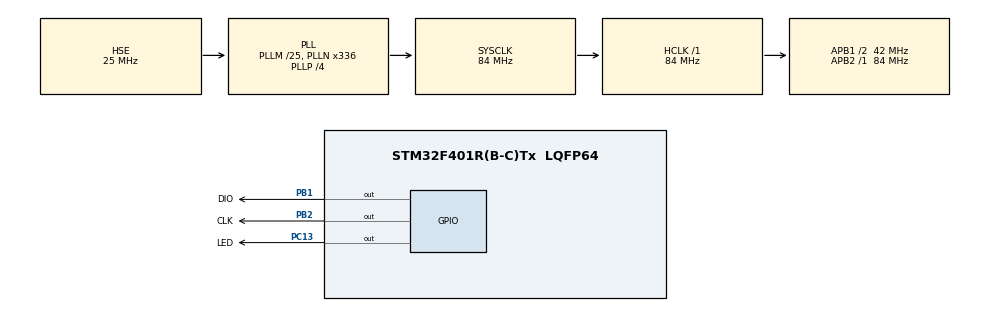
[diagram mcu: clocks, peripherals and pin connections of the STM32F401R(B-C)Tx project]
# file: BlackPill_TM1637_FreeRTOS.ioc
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FREERTOS.Tasks01=defaultTask,24,128,StartDefaultTask,Default,NULL,Dynamic,NULL,NULL
Mcu.Family=STM32F4
Mcu.Name=STM32F401R(B-C)Tx
Mcu.Package=LQFP64
NVIC.PriorityGroup=NVIC_PRIORITYGROUP_4
NVIC.TIM1_TRG_COM_TIM11_IRQn=true\:15\:0\:false\:false\:true\:false\:false\:true\:true
NVIC.TimeBase=TIM1_TRG_COM_TIM11_IRQn
NVIC.TimeBaseIP=TIM11
PB1.GPIO_Label=DIO
PB1.GPIO_ModeDefaultOutputPP=GPIO_MODE_OUTPUT_OD
PB1.GPIO_PuPd=GPIO_NOPULL
PB1.GPIO_Speed=GPIO_SPEED_FREQ_VERY_HIGH
PB1.PinState=GPIO_PIN_SET
PB1.Signal=GPIO_Output
PB2.GPIO_Label=CLK
PB2.GPIO_ModeDefaultOutputPP=GPIO_MODE_OUTPUT_OD
PB2.GPIO_PuPd=GPIO_NOPULL
PB2.GPIO_Speed=GPIO_SPEED_FREQ_VERY_HIGH
PB2.PinState=GPIO_PIN_SET
PB2.Signal=GPIO_Output
PC13-ANTI_TAMP.GPIO_Label=LED
PC13-ANTI_TAMP.Signal=GPIO_Output
PC14-OSC32_IN.Mode=LSE-External-Oscillator
PC14-OSC32_IN.Signal=RCC_OSC32_IN
PC15-OSC32_OUT.Mode=LSE-External-Oscillator
PC15-OSC32_OUT.Signal=RCC_OSC32_OUT
PH0\ -\ OSC_IN.Mode=HSE-External-Oscillator
PH0\ -\ OSC_IN.Signal=RCC_OSC_IN
PH1\ -\ OSC_OUT.Mode=HSE-External-Oscillator
PH1\ -\ OSC_OUT.Signal=RCC_OSC_OUT
ProjectManager.HeapSize=0x200
ProjectManager.StackSize=0x400
ProjectManager.TargetToolchain=CMake
RCC.48MHZClocksFreq_Value=48000000
RCC.AHBFreq_Value=84000000
RCC.APB1CLKDivider=RCC_HCLK_DIV2
RCC.APB1Freq_Value=42000000
RCC.APB1TimFreq_Value=84000000
RCC.APB2Freq_Value=84000000
RCC.APB2TimFreq_Value=84000000
RCC.CortexFreq_Value=84000000
RCC.HCLKFreq_Value=84000000
RCC.HSE_VALUE=25000000
RCC.HSI_VALUE=16000000
RCC.PLLM=25
RCC.PLLN=336
RCC.PLLP=RCC_PLLP_DIV4
RCC.PLLQ=7
RCC.PLLSourceVirtual=RCC_PLLSOURCE_HSE
RCC.SYSCLKFreq_VALUE=84000000
RCC.SYSCLKSource=RCC_SYSCLKSOURCE_PLLCLK
RCC.VCOOutputFreq_Value=336000000
VP_FREERTOS_VS_CMSIS_V2.Mode=CMSIS_V2
VP_SYS_VS_tim11.Mode=TIM11
board=custom

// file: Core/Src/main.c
/* USER CODE BEGIN Header */
/**
  ******************************************************************************
  * @file           : main.c
  * @brief          : Main program body
  ******************************************************************************
  * @attention
  *
  * Copyright (c) 2026 STMicroelectronics.
  * All rights reserved.
  *
  * This software is licensed under terms that can be found in the LICENSE file
  * in the root directory of this software component.
  * If no LICENSE file comes with this software, it is provided AS-IS.
  *
  ******************************************************************************
  */
/* USER CODE END Header */
#include "main.h"
#include "cmsis_os.h"

/* USER CODE BEGIN Includes */
#include "tm1637.h"
/* USER CODE END Includes */

/* Definitions for defaultTask */
osThreadId_t defaultTaskHandle;
const osThreadAttr_t defaultTask_attributes = {
  .name = "defaultTask",
  .stack_size = 128 * 4,
  .priority = (osPriority_t) osPriorityNormal,
};
/* USER CODE BEGIN PV */
TM1637_HandleTypeDef htm1637 = {
  .brightness = 7,
  .digits = 4,
  .clk_port = CLK_GPIO_Port,
  .clk_pin = CLK_Pin,
  .dio_port = DIO_GPIO_Port,
  .dio_pin = DIO_Pin,
};
/* USER CODE END PV */

void SystemClock_Config(void);
static void MX_GPIO_Init(void);
void StartDefaultTask(void *argument);

int main(void)
{

  /* MCU Configuration--------------------------------------------------------*/

  /* Reset of all peripherals, Initializes the Flash interface and the Systick. */
  HAL_Init();

  /* Configure the system clock */
  SystemClock_Config();

  /* Initialize all configured peripherals */
  MX_GPIO_Init();

  /* Init scheduler */
  osKernelInitialize();

  /* USER CODE BEGIN RTOS_MUTEX */
  /* add mutexes, ... */
  TM1637_Init(&htm1637);
  /* USER CODE END RTOS_MUTEX */

  /* Create the thread(s) */
  /* creation of defaultTask */
  defaultTaskHandle = osThreadNew(StartDefaultTask, NULL, &defaultTask_attributes);

  /* USER CODE BEGIN RTOS_THREADS */
  /* add threads, ... */
  TM1637_StartTask(NULL);
  /* USER CODE END RTOS_THREADS */

  /* Start scheduler */
  osKernelStart();

  /* We should never get here as control is now taken by the scheduler */

  /* Infinite loop */
  while (1)
  {
  }

}

void SystemClock_Config(void)
{
  RCC_OscInitTypeDef RCC_OscInitStruct = {0};
  RCC_ClkInitTypeDef RCC_ClkInitStruct = {0};

  /** Configure the main internal regulator output voltage
  */
  __HAL_RCC_PWR_CLK_ENABLE();
  __HAL_PWR_VOLTAGESCALING_CONFIG(PWR_REGULATOR_VOLTAGE_SCALE2);

  /** Initializes the RCC Oscillators according to the specified parameters
  * in the RCC_OscInitTypeDef structure.
  */
  RCC_OscInitStruct.OscillatorType = RCC_OSCILLATORTYPE_HSE;
  RCC_OscInitStruct.HSEState = RCC_HSE_ON;
  RCC_OscInitStruct.PLL.PLLState = RCC_PLL_ON;
  RCC_OscInitStruct.PLL.PLLSource = RCC_PLLSOURCE_HSE;
  RCC_OscInitStruct.PLL.PLLM = 25;
  RCC_OscInitStruct.PLL.PLLN = 336;
  RCC_OscInitStruct.PLL.PLLP = RCC_PLLP_DIV4;
  RCC_OscInitStruct.PLL.PLLQ = 7;
  if (HAL_RCC_OscConfig(&RCC_OscInitStruct) != HAL_OK)
  {
    Error_Handler();
  }

  /** Initializes the CPU, AHB and APB buses clocks
  */
  RCC_ClkInitStruct.ClockType = RCC_CLOCKTYPE_HCLK|RCC_CLOCKTYPE_SYSCLK
                              |RCC_CLOCKTYPE_PCLK1|RCC_CLOCKTYPE_PCLK2;
  RCC_ClkInitStruct.SYSCLKSource = RCC_SYSCLKSOURCE_PLLCLK;
  RCC_ClkInitStruct.AHBCLKDivider = RCC_SYSCLK_DIV1;
  RCC_ClkInitStruct.APB1CLKDivider = RCC_HCLK_DIV2;
  RCC_ClkInitStruct.APB2CLKDivider = RCC_HCLK_DIV1;

  if (HAL_RCC_ClockConfig(&RCC_ClkInitStruct, FLASH_LATENCY_2) != HAL_OK)
  {
    Error_Handler();
  }
}

static void MX_GPIO_Init(void)
{
  GPIO_InitTypeDef GPIO_InitStruct = {0};

  /* GPIO Ports Clock Enable */
  __HAL_RCC_GPIOC_CLK_ENABLE();
  __HAL_RCC_GPIOH_CLK_ENABLE();
  __HAL_RCC_GPIOB_CLK_ENABLE();

  /*Configure GPIO pin Output Level */
  HAL_GPIO_WritePin(LED_GPIO_Port, LED_Pin, GPIO_PIN_RESET);

  /*Configure GPIO pin Output Level */
  HAL_GPIO_WritePin(GPIOB, DIO_Pin|CLK_Pin, GPIO_PIN_SET);

  /*Configure GPIO pin : LED_Pin */
  GPIO_InitStruct.Pin = LED_Pin;
  GPIO_InitStruct.Mode = GPIO_MODE_OUTPUT_PP;
  GPIO_InitStruct.Pull = GPIO_NOPULL;
  GPIO_InitStruct.Speed = GPIO_SPEED_FREQ_LOW;
  HAL_GPIO_Init(LED_GPIO_Port, &GPIO_InitStruct);

  /*Configure GPIO pins : DIO_Pin CLK_Pin */
  GPIO_InitStruct.Pin = DIO_Pin|CLK_Pin;
  GPIO_InitStruct.Mode = GPIO_MODE_OUTPUT_OD;
  GPIO_InitStruct.Pull = GPIO_NOPULL;
  GPIO_InitStruct.Speed = GPIO_SPEED_FREQ_VERY_HIGH;
  HAL_GPIO_Init(GPIOB, &GPIO_InitStruct);

}

void StartDefaultTask(void *argument)
{
  /* USER CODE BEGIN 5 */
  unsigned i = 0;
  /* Infinite loop */
  for(;;)
  {
    HAL_GPIO_TogglePin(LED_GPIO_Port, LED_Pin);
    TM1637_printf(&htm1637, "V.%u", i++);
    osDelay(1000);
  }
  /* USER CODE END 5 */
}

void HAL_TIM_PeriodElapsedCallback(TIM_HandleTypeDef *htim)
{
  if (htim->Instance == TIM11)
  {
    HAL_IncTick();
  }
}

void Error_Handler(void)
{
  __disable_irq();
  while (1)
  {
  }
}
